# upp_model: IP-XACT component
VLNV IcronTechnologies:IcronTechnologies:upp_model:1.0

## Parameters
addr_width = 10
bus_width = 32

## Bus interfaces (logical=physical port)
default_map: slave AGNISYS:AGNISYS:APB:1.0, memory map uppmap
  pclk=pclk, presetn=presetn, psel=psel, penable=penable, pwrite=pwrite, pprot=pprot, pstrb=pstrb, pwdata=pwdata, paddr=paddr, pready=pready, prdata=prdata, pslverr=pslverr

## Ports
in pclk
in presetn
in psel
in penable
in pwrite
in pprot[2:0]
in pstrb[(bus_width div 8 )-1:0]
in pwdata[bus_width -1:0]
in paddr[addr_width -1:0]
out pready
out prdata[bus_width -1:0]
out pslverr
out upp_regsversion_major_r[7:0]
out upp_regsversion_minor_r[7:0]
out upp_regsversion_patch_r[7:0]
out upp_regsconfig0_enb
out upp_regsconfig0_ping_non_rspns_cnt_r[3:0]
out upp_regsconfig0_dp_max_numb_cnt_r[6:0]
out upp_regsconfig0_dp_max_time_cnt_r[8:0]
out upp_regscontrol_enb
out upp_regscontrol_limit_num_pings_snt_r
out upp_regscontrol_iso_dev_non_rspns_cnt_r[3:0]
out upp_regscontrol_lex_buff_max_cnt_r[5:0]
out upp_regscontrol_disable_itp_delta_r
out upp_regscontrol_max_itp_deviation_2fix_r[9:0]
out upp_regscontrol_limit_max_burst_r
out upp_regscontrol_bulk_term_en_r
out upp_regscontrol_ping_term_en_r
out upp_regscontrol_ctrl_trfr_int_mode_r
out upp_regscontrol_init_ept_r
out upp_regscontrol_itp_gen_r
out upp_regscontrol_itp_manager_en_r
out upp_regscontrol_ctrl_manager_en_r
out upp_regscontrol_clr_ctrl_trfr_mgr_r
out upp_regsid_mgr_fifo_write_engine_config0_clear_enb
out upp_regsid_mgr_fifo_write_engine_config0_clear_wclr_r
out upp_regsid_mgr_fifo_write_engine_config0_mode_enb
out upp_regsid_mgr_fifo_write_engine_config0_mode_drp_on_sop_r
out upp_regsid_mgr_fifo_write_engine_config0_mode_drp_on_pkt_err_r
out upp_regsid_mgr_fifo_write_engine_config0_mode_pkt_strm_r
out upp_regsid_mgr_fifo_write_engine_config0_mode_flw_ctrl_en_r
out upp_regsid_mgr_fifo_write_engine_config0_notify_limit_enb
out upp_regsid_mgr_fifo_write_engine_config0_notify_limit_ntfy_lmt_r[31:0]
out upp_regsid_mgr_fifo_write_engine_stats0_rd2clr_config_rd_valid_out
out upp_regsid_mgr_fifo_write_engine_stats0_rd2clr_config_wr_valid_out
out upp_regsid_mgr_fifo_write_engine_stats0_nfifo_dcount_rd_valid_out
out upp_regsid_mgr_fifo_write_engine_stats0_pfifo_dcount_rd_valid_out
out upp_regsid_mgr_fifo_write_engine_stats0_pkt_max_byte_cnt_err_rd_valid_out
out upp_regsid_mgr_fifo_write_engine_stats0_fifo_full_err_rd_valid_out
out upp_regsid_mgr_fifo_write_engine_stats0_pkt_err_rd_valid_out
out upp_regsid_mgr_fifo_write_engine_stats0_pkt_sop_err_rd_valid_out
out upp_regsid_mgr_fifo_write_engine_stats0_wflush_act_rd_valid_out
out upp_regsid_mgr_fifo_write_engine_stats0_drp_pkt_rd_rd_valid_out
out upp_regsid_mgr_fifo_write_engine_stats0_drp_pkt_wr_rd_valid_out
out upp_regsid_mgr_fifo_write_engine_stats0_flow_ctrl_rd_valid_out
out upp_regsid_mgr_fifo_read_engine_config0_clear_enb
out upp_regsid_mgr_fifo_read_engine_config0_clear_rclr_r
out upp_regsid_mgr_fifo_read_engine_stats0_rd2clr_config_rd_valid_out
out upp_regsid_mgr_fifo_read_engine_stats0_rd2clr_config_wr_valid_out
out upp_regsid_mgr_fifo_read_engine_stats0_rflush_act_rd_valid_out
out upp_regsid_mgr_fifo_read_engine_stats0_drp_pkt_rd_valid_out
out upp_regsid_mgr_fifo_read_engine_stats0_flow_ctrl_rd_valid_out
out upp_regsiso_lex_fifo_{n}_write_engine_config0_clear_enb (n=0..3)
out upp_regsiso_lex_fifo_{n}_write_engine_config0_clear_wclr_r (n=0..3)
out upp_regsiso_lex_fifo_{n}_write_engine_config0_mode_enb (n=0..3)
out upp_regsiso_lex_fifo_{n}_write_engine_config0_mode_drp_on_sop_r (n=0..3)
out upp_regsiso_lex_fifo_{n}_write_engine_config0_mode_drp_on_pkt_err_r (n=0..3)
out upp_regsiso_lex_fifo_{n}_write_engine_config0_mode_pkt_strm_r (n=0..3)
out upp_regsiso_lex_fifo_{n}_write_engine_config0_mode_flw_ctrl_en_r (n=0..3)
out upp_regsiso_lex_fifo_{n}_write_engine_config0_notify_limit_enb (n=0..3)
out upp_regsiso_lex_fifo_{n}_write_engine_config0_notify_limit_ntfy_lmt_r[31:0] (n=0..3)
out upp_regsiso_lex_fifo_{n}_write_engine_stats0_rd2clr_config_rd_valid_out (n=0..3)
out upp_regsiso_lex_fifo_{n}_write_engine_stats0_rd2clr_config_wr_valid_out (n=0..3)
out upp_regsiso_lex_fifo_{n}_write_engine_stats0_nfifo_dcount_rd_valid_out (n=0..3)
out upp_regsiso_lex_fifo_{n}_write_engine_stats0_pfifo_dcount_rd_valid_out (n=0..3)
out upp_regsiso_lex_fifo_{n}_write_engine_stats0_pkt_max_byte_cnt_err_rd_valid_out (n=0..3)
out upp_regsiso_lex_fifo_{n}_write_engine_stats0_fifo_full_err_rd_valid_out (n=0..3)
out upp_regsiso_lex_fifo_{n}_write_engine_stats0_pkt_err_rd_valid_out (n=0..3)
out upp_regsiso_lex_fifo_{n}_write_engine_stats0_pkt_sop_err_rd_valid_out (n=0..3)
out upp_regsiso_lex_fifo_{n}_write_engine_stats0_wflush_act_rd_valid_out (n=0..3)
out upp_regsiso_lex_fifo_{n}_write_engine_stats0_drp_pkt_rd_rd_valid_out (n=0..3)
out upp_regsiso_lex_fifo_{n}_write_engine_stats0_drp_pkt_wr_rd_valid_out (n=0..3)
out upp_regsiso_lex_fifo_{n}_write_engine_stats0_flow_ctrl_rd_valid_out (n=0..3)
out upp_regsiso_lex_fifo_{n}_read_engine_config0_clear_enb (n=0..3)
out upp_regsiso_lex_fifo_{n}_read_engine_config0_clear_rclr_r (n=0..3)
out upp_regsiso_lex_fifo_{n}_read_engine_stats0_rd2clr_config_rd_valid_out (n=0..3)
out upp_regsiso_lex_fifo_{n}_read_engine_stats0_rd2clr_config_wr_valid_out (n=0..3)
out upp_regsiso_lex_fifo_{n}_read_engine_stats0_rflush_act_rd_valid_out (n=0..3)
out upp_regsiso_lex_fifo_{n}_read_engine_stats0_drp_pkt_rd_valid_out (n=0..3)
out upp_regsiso_lex_fifo_{n}_read_engine_stats0_flow_ctrl_rd_valid_out (n=0..3)
out upp_regsiso_rex_fifo_write_engine_config0_clear_enb
out upp_regsiso_rex_fifo_write_engine_config0_clear_wclr_r
out upp_regsiso_rex_fifo_write_engine_config0_mode_enb
out upp_regsiso_rex_fifo_write_engine_config0_mode_drp_on_sop_r
out upp_regsiso_rex_fifo_write_engine_config0_mode_drp_on_pkt_err_r
out upp_regsiso_rex_fifo_write_engine_config0_mode_pkt_strm_r
out upp_regsiso_rex_fifo_write_engine_config0_mode_flw_ctrl_en_r
out upp_regsiso_rex_fifo_write_engine_config0_notify_limit_enb
out upp_regsiso_rex_fifo_write_engine_config0_notify_limit_ntfy_lmt_r[31:0]
out upp_regsiso_rex_fifo_write_engine_stats0_rd2clr_config_rd_valid_out
out upp_regsiso_rex_fifo_write_engine_stats0_rd2clr_config_wr_valid_out
out upp_regsiso_rex_fifo_write_engine_stats0_nfifo_dcount_rd_valid_out
out upp_regsiso_rex_fifo_write_engine_stats0_pfifo_dcount_rd_valid_out
out upp_regsiso_rex_fifo_write_engine_stats0_pkt_max_byte_cnt_err_rd_valid_out
out upp_regsiso_rex_fifo_write_engine_stats0_fifo_full_err_rd_valid_out
out upp_regsiso_rex_fifo_write_engine_stats0_pkt_err_rd_valid_out
out upp_regsiso_rex_fifo_write_engine_stats0_pkt_sop_err_rd_valid_out
out upp_regsiso_rex_fifo_write_engine_stats0_wflush_act_rd_valid_out
out upp_regsiso_rex_fifo_write_engine_stats0_drp_pkt_rd_rd_valid_out
out upp_regsiso_rex_fifo_write_engine_stats0_drp_pkt_wr_rd_valid_out
out upp_regsiso_rex_fifo_write_engine_stats0_flow_ctrl_rd_valid_out
out upp_regsiso_rex_fifo_read_engine_config0_clear_enb
out upp_regsiso_rex_fifo_read_engine_config0_clear_rclr_r
out upp_regsiso_rex_fifo_read_engine_stats0_rd2clr_config_rd_valid_out
out upp_regsiso_rex_fifo_read_engine_stats0_rd2clr_config_wr_valid_out
out upp_regsiso_rex_fifo_read_engine_stats0_rflush_act_rd_valid_out
out upp_regsiso_rex_fifo_read_engine_stats0_drp_pkt_rd_valid_out
out upp_regsiso_rex_fifo_read_engine_stats0_flow_ctrl_rd_valid_out
out upp_regsctrl_trfr_h2d_fifo_write_engine_config0_clear_enb
out upp_regsctrl_trfr_h2d_fifo_write_engine_config0_clear_wclr_r
out upp_regsctrl_trfr_h2d_fifo_write_engine_config0_mode_enb
out upp_regsctrl_trfr_h2d_fifo_write_engine_config0_mode_drp_on_sop_r
out upp_regsctrl_trfr_h2d_fifo_write_engine_config0_mode_drp_on_pkt_err_r
out upp_regsctrl_trfr_h2d_fifo_write_engine_config0_mode_pkt_strm_r
out upp_regsctrl_trfr_h2d_fifo_write_engine_config0_mode_flw_ctrl_en_r
out upp_regsctrl_trfr_h2d_fifo_write_engine_config0_notify_limit_enb
out upp_regsctrl_trfr_h2d_fifo_write_engine_config0_notify_limit_ntfy_lmt_r[31:0]
out upp_regsctrl_trfr_h2d_fifo_write_engine_stats0_rd2clr_config_rd_valid_out
out upp_regsctrl_trfr_h2d_fifo_write_engine_stats0_rd2clr_config_wr_valid_out
out upp_regsctrl_trfr_h2d_fifo_write_engine_stats0_nfifo_dcount_rd_valid_out
out upp_regsctrl_trfr_h2d_fifo_write_engine_stats0_pfifo_dcount_rd_valid_out
out upp_regsctrl_trfr_h2d_fifo_write_engine_stats0_pkt_max_byte_cnt_err_rd_valid_out
out upp_regsctrl_trfr_h2d_fifo_write_engine_stats0_fifo_full_err_rd_valid_out
out upp_regsctrl_trfr_h2d_fifo_write_engine_stats0_pkt_err_rd_valid_out
out upp_regsctrl_trfr_h2d_fifo_write_engine_stats0_pkt_sop_err_rd_valid_out
out upp_regsctrl_trfr_h2d_fifo_write_engine_stats0_wflush_act_rd_valid_out
out upp_regsctrl_trfr_h2d_fifo_write_engine_stats0_drp_pkt_rd_rd_valid_out
out upp_regsctrl_trfr_h2d_fifo_write_engine_stats0_drp_pkt_wr_rd_valid_out
out upp_regsctrl_trfr_h2d_fifo_write_engine_stats0_flow_ctrl_rd_valid_out
out upp_regsctrl_trfr_h2d_fifo_read_engine_config0_clear_enb
out upp_regsctrl_trfr_h2d_fifo_read_engine_config0_clear_rclr_r
out upp_regsctrl_trfr_h2d_fifo_read_engine_stats0_rd2clr_config_rd_valid_out
out upp_regsctrl_trfr_h2d_fifo_read_engine_stats0_rd2clr_config_wr_valid_out
out upp_regsctrl_trfr_h2d_fifo_read_engine_stats0_rflush_act_rd_valid_out
out upp_regsctrl_trfr_h2d_fifo_read_engine_stats0_drp_pkt_rd_valid_out
out upp_regsctrl_trfr_h2d_fifo_read_engine_stats0_flow_ctrl_rd_valid_out
out upp_regsctrl_trfr_d2h_fifo_write_engine_config0_clear_enb
out upp_regsctrl_trfr_d2h_fifo_write_engine_config0_clear_wclr_r
out upp_regsctrl_trfr_d2h_fifo_write_engine_config0_mode_enb
out upp_regsctrl_trfr_d2h_fifo_write_engine_config0_mode_drp_on_sop_r
out upp_regsctrl_trfr_d2h_fifo_write_engine_config0_mode_drp_on_pkt_err_r
out upp_regsctrl_trfr_d2h_fifo_write_engine_config0_mode_pkt_strm_r
out upp_regsctrl_trfr_d2h_fifo_write_engine_config0_mode_flw_ctrl_en_r
out upp_regsctrl_trfr_d2h_fifo_write_engine_config0_notify_limit_enb
out upp_regsctrl_trfr_d2h_fifo_write_engine_config0_notify_limit_ntfy_lmt_r[31:0]
out upp_regsctrl_trfr_d2h_fifo_write_engine_stats0_rd2clr_config_rd_valid_out
out upp_regsctrl_trfr_d2h_fifo_write_engine_stats0_rd2clr_config_wr_valid_out
out upp_regsctrl_trfr_d2h_fifo_write_engine_stats0_nfifo_dcount_rd_valid_out
out upp_regsctrl_trfr_d2h_fifo_write_engine_stats0_pfifo_dcount_rd_valid_out
out upp_regsctrl_trfr_d2h_fifo_write_engine_stats0_pkt_max_byte_cnt_err_rd_valid_out
out upp_regsctrl_trfr_d2h_fifo_write_engine_stats0_fifo_full_err_rd_valid_out
out upp_regsctrl_trfr_d2h_fifo_write_engine_stats0_pkt_err_rd_valid_out
out upp_regsctrl_trfr_d2h_fifo_write_engine_stats0_pkt_sop_err_rd_valid_out
out upp_regsctrl_trfr_d2h_fifo_write_engine_stats0_wflush_act_rd_valid_out
out upp_regsctrl_trfr_d2h_fifo_write_engine_stats0_drp_pkt_rd_rd_valid_out
out upp_regsctrl_trfr_d2h_fifo_write_engine_stats0_drp_pkt_wr_rd_valid_out
out upp_regsctrl_trfr_d2h_fifo_write_engine_stats0_flow_ctrl_rd_valid_out
out upp_regsctrl_trfr_d2h_fifo_read_engine_config0_clear_enb
out upp_regsctrl_trfr_d2h_fifo_read_engine_config0_clear_rclr_r
out upp_regsctrl_trfr_d2h_fifo_read_engine_stats0_rd2clr_config_rd_valid_out
out upp_regsctrl_trfr_d2h_fifo_read_engine_stats0_rd2clr_config_wr_valid_out
out upp_regsctrl_trfr_d2h_fifo_read_engine_stats0_rflush_act_rd_valid_out
out upp_regsctrl_trfr_d2h_fifo_read_engine_stats0_drp_pkt_rd_valid_out
out upp_regsctrl_trfr_d2h_fifo_read_engine_stats0_flow_ctrl_rd_valid_out
out upp_regsctrl_trfr_h2d_data_rd_valid_out
out upp_regsctrl_trfr_h2d_ctrl_rd_valid_out
out upp_regsctrl_trfr_h2d_skip_enb
out upp_regsctrl_trfr_h2d_skip_cycles_r[7:0]
out upp_regsregctrl_trfr_h2d_skip_cycles_wr_pulse
out upp_regsctrl_trfr_h2d_dbg_enb
out upp_regsctrl_trfr_h2d_dbg_squelch_en_r
out upp_regsctrl_trfr_h2d_dbg_crc32_term_value_r[9:0]
out upp_regsctrl_trfr_h2d_dbg_crc32_err_inj_en_r
out upp_regsctrl_trfr_d2h_data_rd_valid_out
out upp_regsctrl_trfr_d2h_ctrl_rd_valid_out
out upp_regsctrl_trfr_d2h_skip_enb
out upp_regsctrl_trfr_d2h_skip_cycles_r[7:0]
out upp_regsregctrl_trfr_d2h_skip_cycles_wr_pulse
out upp_regsctrl_trfr_d2h_dbg_enb
out upp_regsctrl_trfr_d2h_dbg_squelch_en_r
out upp_regsctrl_trfr_d2h_dbg_crc32_term_value_r[9:0]
out upp_regsctrl_trfr_d2h_dbg_crc32_err_inj_en_r
out upp_regsctrl_trfr_cmpltd_enb
out upp_regsctrl_trfr_cmpltd_device_addr_r[6:0]
out upp_regsregctrl_trfr_cmpltd_device_addr_wr_pulse
out upp_regsendpoint_tbl_config0_enb
out upp_regsendpoint_tbl_config0_null_en_r
out upp_regsendpoint_tbl_config0_bm_attributes_tt_r[1:0]
out upp_regsendpoint_tbl_config0_qid_r[7:0]
out upp_regsendpoint_tbl_config0_device_addr_r[6:0]
out upp_regsendpoint_tbl_config0_ept_num_r[3:0]
out upp_regsregendpoint_tbl_config0_ept_num_wr_pulse
out upp_regsendpoint_tbl_config1_enb
out upp_regsendpoint_tbl_config1_crdt_chk_value_r[1:0]
out upp_regsendpoint_tbl_config1_max_burst_r[3:0]
out upp_regsendpoint_tbl_config1_coded_binterval_r[15:0]
out upp_regsstats0_rd2clr_config_rd_valid_out
out upp_regsstats0_rd2clr_config_wr_valid_out
out upp_regsstats0_missing_itp_rd_valid_out

## Address spaces and blocks
uppmap.upp: base 0x000, range 0x300, width 32

## Registers
Registers are 32-bit, read-only, reset 0x0 unless marked. A register's access mark holds for its fields unless they carry their own. Offsets are from the block's base; lines under a group give offsets from that group; [hi:lo] are bit positions; {n}, {i} and the like mark numbered series; 'fields as' and 'values as' point back to an identical list; <NAME> marks a mode.

## uppmap.upp — UPP Registers
Base 0x00000000
0x00 version reset 0x40400 — Version: 2.0.0: Adding the Control Transfer Manager and CT-Processor to the Design 3.0.0: Adding the ITP Manager, Endpoint Table, CTIM Time Tag and Skip Function, etc 3.1.0: Adding Max Burst to the Endpoint Table 3.2.0: Changed the Interrupt Pending to avoid blocking the register update when enable is 0 3.3.0: Added pending_irq register and Add Ping and Bulk IN Termination 4.0.0: Adding BInterval and Independent ISO REX Scheduling for Service Interval Binning. Also, add LEX PFIFOs and ITP Registers 4.1.0: Cleanup register map and added ISO Null Queue 4.1.1: Removed mark_debug and also added read pipline for the PFIFO to improve timing 4.2.0: Add interrupts for ISO Device Non-Response. 4.3.0: Add interrupts for PING not responding 4.3.1: Remove Latches 4.4.0: Use CPU Plug IPs rather than stand alone logic for h2d and d2h
  [23:16] major — Major version
  [15:8] minor — Minor version
  [7:0] patch — Patch version
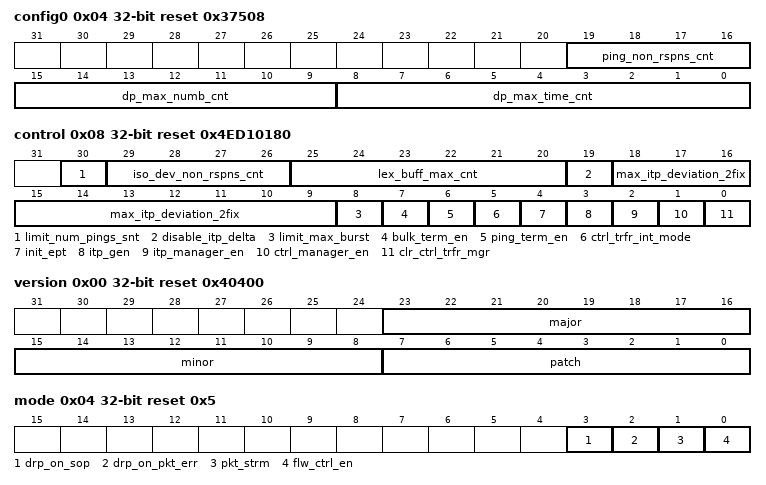
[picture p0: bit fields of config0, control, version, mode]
0x04 config0 rw reset 0x37508
  [19:16] ping_non_rspns_cnt — Every Service Interval when a PING is sent to the device and a PING RESPONSE is not received, a count is incremented. When the counter reaches this value, it will issue an interrupt to software
  [15:9] dp_max_numb_cnt — This is the total number of full-size DP packets that needs to be allocated in one ITP. This value together with dp_max_time_cnt divide an ITP period into multiple section of available "credits". The "credits" are used to schedule ISO packets such that they don't fall on ITP boundary.
  [8:0] dp_max_time_cnt — Maximum "cycle" time for one DP packet. This is typically 2.117 us and for our 4-byte implementation and clock period of 8 ns (125MHz frequency) it is about 264. This counter value with the help of dp_max_numb_cnt divide an ITP period into multiple sections of available "credits". The "credits" are used to schedule ISO packets such that they don't fall on ITP boundary.
0x08 control rw reset 0x4ED10180
  [30] limit_num_pings_snt — Set to 1 to limit the number of PING Request sent to one PING in every 2ms (when device is not responding to PING). To avoid flooding the REX Hub that can cause credit_hp_timer firing, the default is enabled such that it only sends a PING requests every ~2ms when device is not responding (when device is disconnected).
  [29:26] iso_dev_non_rspns_cnt — Every Service Interval when the device is asked for data and it does not respond at least with one DP, a count is incremented. When the counter reaches this value, it will issue an interrupt to software.
  [25:20] lex_buff_max_cnt — This is maximum full DP size of the LEX buffers in each ISO (accelerated) queue. This is used on the REX to follow the buffer occupancy on the LEX. Typical value should be less than 45
  [19] disable_itp_delta — Set to 1 to disable modifying the ITP Delta field in the Isochronous Timestamp (ITS) of Table 8-26 Section 8.7.
  [18:9] max_itp_deviation_2fix — Maximum deviation of incoming ITP from Bus Boundary for the ITP Manager to fix immediately. This number should be (deviation us/8 ns). Default value of 128 represents about 1us deviation
  [8] limit_max_burst — Set to 0 to let the REX ISO Scheduler to base its burst size on the device Max Burst. By default, the burst size follows the host value.
  [7] bulk_term_en — Set to 0 to disable BULK IN Termination Method (BITM)
  [6] ping_term_en — Set to 1 to enable the Ping Termination Method (PTM) that terminates the PING protocol in UPP
  [5] ctrl_trfr_int_mode — When 0, the ctrl_trfr (h2d and d2h) interrupts are packet based (rising sop). When 1, the interrupt is cycle based (each srdy causes interrupt)
  [4] init_ept — Assert high to clear and initialize the EndPoint Table (EPT).
  [3] itp_gen — Assert high to instruct the ITP Manager on the REX, when it is enabled, to independently start sending ITP packets to the device as soon as its Link Layer is in U0.
  [2] itp_manager_en — Assert high to have the ITP Manager on the REX enabled such that it can track the ITPs from the Host and independently issue an ITP when the 125us timer elapses and no ITP is received.
  [1] ctrl_manager_en — Assert high to enable the Control Transfer Manager. When not enabled, the UPP does not interfere with or terminate Control Transfers. As the result, Host and Device will interact directly.
  [0] clr_ctrl_trfr_mgr — Assert high to clear all the state tables in the Control Transfer Manager
0x0C id_mgr_fifo group
  0x00 version reset 0x10100 — Version 1.1.0: Added Icron Attributes for stats script generation
    fields as version
  0x04 write_engine group
    0x00 config0 group
      0x00 clear rw — Synchronous clear for the write clock domain
        [0] wclr
      0x04 mode rw reset 0x5
        [3] drp_on_sop — When set, drops the current packet without writing it to the buffer. See Wiki
        [2] drp_on_pkt_err — When set, removes the packet from the buffer without presenting it to the output interface upon the ERR bit being set before the notification point. See Wiki
        [1] pkt_strm — Selects packet based or streaming based behavior. See Wiki
        [0] flw_ctrl_en — Enables the flow control. See Wiki
      0x08 notify_limit rw
        [31:0] ntfy_lmt — Sets the number of words required to be written into the packet FIFO before a notification will be generated. See wiki
    0x0C stats0 group — All the Statistic Registers and their configuration for the Write Engine
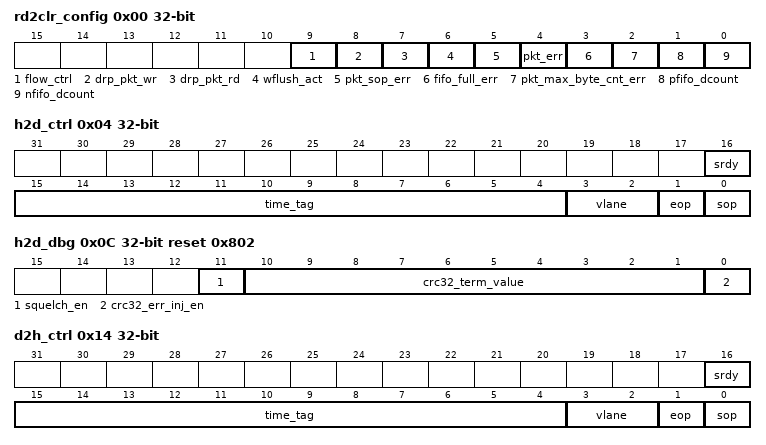
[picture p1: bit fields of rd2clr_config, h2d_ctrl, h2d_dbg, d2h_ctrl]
      0x00 rd2clr_config rw — Configures if the stats register read by s/w clears the read register. A 1 in any bit configures the h/w to clear the corresponding stats register after a s/w read of that stats register.
        [9] flow_ctrl, [8] drp_pkt_wr, [7] drp_pkt_rd, [6] wflush_act, [5] pkt_sop_err, [4] pkt_err, [3] fifo_full_err, [2] pkt_max_byte_cnt_err, [1] pfifo_dcount, [0] nfifo_dcount
      0x04 nfifo_dcount — Current level for the notification FIFO in the PFIFO
        [15:0] nfifo_dcount — _icron_water_marker_ _icron_no_counter_
      0x08 pfifo_dcount — Current level for the packet FIFO in the PFIFO
        [15:0] pfifo_dcount — _icron_water_marker_ _icron_no_counter_
      0x0C pkt_max_byte_cnt_err — The count for capped packets in PFIFO write engine, as the result of reaching maximum size in the PFIFO
        [7:0] pkt_max_byte_cnt_err
      0x10 fifo_full_err — The count for either of PFIFO or NFIFO being full
        [7:0] fifo_full_err
      0x14 pkt_err — The count of packets tagged to be dropped later in the PFIFO read engine
        [7:0] pkt_err
      0x18 pkt_sop_err — The count of packets flushed in the PFIFO during the SOP phase
        [7:0] pkt_sop_err
      0x1C wflush_act — The count of capped packets in the PFIFO. Note that back-to-back packets are counted as one if they are both capped.
        [7:0] wflush_act — _icron_event_detect_rising_edge_
      0x20 drp_pkt_rd — The count of drop packets flagged to be dropped by the read engine
        [7:0] drp_pkt_rd
      0x24 drp_pkt_wr — The count of drop packets by the write engine
        [7:0] drp_pkt_wr
      0x28 flow_ctrl — The count of the clock cycles the DRDY is asserted low resulting in flow control
        [15:0] flow_ctrl
  0x3C read_engine group
    0x00 config0 group
      0x00 clear rw — Synchronous clear for the read clock domain
        [0] rclr
    0x04 stats0 group — All the Statistic Registers and their configuration for the Read Engine
      0x00 rd2clr_config rw — Configures if the stats register read by s/w clears the read register. A 1 in any bit configures the h/w to clear the corresponding stats register after a s/w read of that stats register.
        [2] flow_ctrl, [1] drp_pkt, [0] rflush_act
      0x04 rflush_act — The counts of number of packets flushed from the PFIFO.
        [7:0] rflush_act — _icron_event_detect_rising_edge_
      0x08 drp_pkt — The counts of drop packet in the PFIFO read engine
        [7:0] drp_pkt
      0x0C flow_ctrl — The count of the clock cycles the DRDY is asserted low resulting in flow control
        [15:0] flow_ctrl
{0x5C+0x50*i} iso_lex_fifo_{i} group (i=0..3)
  0x00 version reset 0x10100 — Version 1.1.0: Added Icron Attributes for stats script generation
    fields as version
  0x04 write_engine group
    0x00 config0 group
      0x00 clear rw — Synchronous clear for the write clock domain
        [0] wclr
      0x04 mode rw reset 0x5
        fields as id_mgr_fifo.write_engine.config0.mode
      0x08 notify_limit rw
        fields as id_mgr_fifo.write_engine.config0.notify_limit
    0x0C stats0 group — All the Statistic Registers and their configuration for the Write Engine
      0x00 rd2clr_config rw — Configures if the stats register read by s/w clears the read register. A 1 in any bit configures the h/w to clear the corresponding stats register after a s/w read of that stats register.
        fields as id_mgr_fifo.write_engine.stats0.rd2clr_config
      0x04 nfifo_dcount — Current level for the notification FIFO in the PFIFO
        [15:0] nfifo_dcount — _icron_water_marker_ _icron_no_counter_
      0x08 pfifo_dcount — Current level for the packet FIFO in the PFIFO
        [15:0] pfifo_dcount — _icron_water_marker_ _icron_no_counter_
      0x0C pkt_max_byte_cnt_err — The count for capped packets in PFIFO write engine, as the result of reaching maximum size in the PFIFO
        [7:0] pkt_max_byte_cnt_err
      0x10 fifo_full_err — The count for either of PFIFO or NFIFO being full
        [7:0] fifo_full_err
      0x14 pkt_err — The count of packets tagged to be dropped later in the PFIFO read engine
        [7:0] pkt_err
      0x18 pkt_sop_err — The count of packets flushed in the PFIFO during the SOP phase
        [7:0] pkt_sop_err
      0x1C wflush_act — The count of capped packets in the PFIFO. Note that back-to-back packets are counted as one if they are both capped.
        [7:0] wflush_act — _icron_event_detect_rising_edge_
      0x20 drp_pkt_rd — The count of drop packets flagged to be dropped by the read engine
        [7:0] drp_pkt_rd
      0x24 drp_pkt_wr — The count of drop packets by the write engine
        [7:0] drp_pkt_wr
      0x28 flow_ctrl — The count of the clock cycles the DRDY is asserted low resulting in flow control
        [15:0] flow_ctrl
  0x3C read_engine group
    0x00 config0 group
      0x00 clear rw — Synchronous clear for the read clock domain
        [0] rclr
    0x04 stats0 group — All the Statistic Registers and their configuration for the Read Engine
      0x00 rd2clr_config rw — Configures if the stats register read by s/w clears the read register. A 1 in any bit configures the h/w to clear the corresponding stats register after a s/w read of that stats register.
        [2] flow_ctrl, [1] drp_pkt, [0] rflush_act
      0x04 rflush_act — The counts of number of packets flushed from the PFIFO.
        [7:0] rflush_act — _icron_event_detect_rising_edge_
      0x08 drp_pkt — The counts of drop packet in the PFIFO read engine
        [7:0] drp_pkt
      0x0C flow_ctrl — The count of the clock cycles the DRDY is asserted low resulting in flow control
        [15:0] flow_ctrl
0x19C iso_rex_fifo group
  0x00 version reset 0x10100 — Version 1.1.0: Added Icron Attributes for stats script generation
    fields as version
  0x04 write_engine group
    0x00 config0 group
      0x00 clear rw — Synchronous clear for the write clock domain
        [0] wclr
      0x04 mode rw reset 0x5
        fields as id_mgr_fifo.write_engine.config0.mode
      0x08 notify_limit rw
        fields as id_mgr_fifo.write_engine.config0.notify_limit
    0x0C stats0 group — All the Statistic Registers and their configuration for the Write Engine
      0x00 rd2clr_config rw — Configures if the stats register read by s/w clears the read register. A 1 in any bit configures the h/w to clear the corresponding stats register after a s/w read of that stats register.
        fields as id_mgr_fifo.write_engine.stats0.rd2clr_config
      0x04 nfifo_dcount — Current level for the notification FIFO in the PFIFO
        [15:0] nfifo_dcount — _icron_water_marker_ _icron_no_counter_
      0x08 pfifo_dcount — Current level for the packet FIFO in the PFIFO
        [15:0] pfifo_dcount — _icron_water_marker_ _icron_no_counter_
      0x0C pkt_max_byte_cnt_err — The count for capped packets in PFIFO write engine, as the result of reaching maximum size in the PFIFO
        [7:0] pkt_max_byte_cnt_err
      0x10 fifo_full_err — The count for either of PFIFO or NFIFO being full
        [7:0] fifo_full_err
      0x14 pkt_err — The count of packets tagged to be dropped later in the PFIFO read engine
        [7:0] pkt_err
      0x18 pkt_sop_err — The count of packets flushed in the PFIFO during the SOP phase
        [7:0] pkt_sop_err
      0x1C wflush_act — The count of capped packets in the PFIFO. Note that back-to-back packets are counted as one if they are both capped.
        [7:0] wflush_act — _icron_event_detect_rising_edge_
      0x20 drp_pkt_rd — The count of drop packets flagged to be dropped by the read engine
        [7:0] drp_pkt_rd
      0x24 drp_pkt_wr — The count of drop packets by the write engine
        [7:0] drp_pkt_wr
      0x28 flow_ctrl — The count of the clock cycles the DRDY is asserted low resulting in flow control
        [15:0] flow_ctrl
  0x3C read_engine group
    0x00 config0 group
      0x00 clear rw — Synchronous clear for the read clock domain
        [0] rclr
    0x04 stats0 group — All the Statistic Registers and their configuration for the Read Engine
      0x00 rd2clr_config rw — Configures if the stats register read by s/w clears the read register. A 1 in any bit configures the h/w to clear the corresponding stats register after a s/w read of that stats register.
        [2] flow_ctrl, [1] drp_pkt, [0] rflush_act
      0x04 rflush_act — The counts of number of packets flushed from the PFIFO.
        [7:0] rflush_act — _icron_event_detect_rising_edge_
      0x08 drp_pkt — The counts of drop packet in the PFIFO read engine
        [7:0] drp_pkt
      0x0C flow_ctrl — The count of the clock cycles the DRDY is asserted low resulting in flow control
        [15:0] flow_ctrl
0x1EC ctrl_trfr_h2d_fifo group
  0x00 version reset 0x10100 — Version 1.1.0: Added Icron Attributes for stats script generation
    fields as version
  0x04 write_engine group
    0x00 config0 group
      0x00 clear rw — Synchronous clear for the write clock domain
        [0] wclr
      0x04 mode rw reset 0x5
        fields as id_mgr_fifo.write_engine.config0.mode
      0x08 notify_limit rw
        fields as id_mgr_fifo.write_engine.config0.notify_limit
    0x0C stats0 group — All the Statistic Registers and their configuration for the Write Engine
      0x00 rd2clr_config rw — Configures if the stats register read by s/w clears the read register. A 1 in any bit configures the h/w to clear the corresponding stats register after a s/w read of that stats register.
        fields as id_mgr_fifo.write_engine.stats0.rd2clr_config
      0x04 nfifo_dcount — Current level for the notification FIFO in the PFIFO
        [15:0] nfifo_dcount — _icron_water_marker_ _icron_no_counter_
      0x08 pfifo_dcount — Current level for the packet FIFO in the PFIFO
        [15:0] pfifo_dcount — _icron_water_marker_ _icron_no_counter_
      0x0C pkt_max_byte_cnt_err — The count for capped packets in PFIFO write engine, as the result of reaching maximum size in the PFIFO
        [7:0] pkt_max_byte_cnt_err
      0x10 fifo_full_err — The count for either of PFIFO or NFIFO being full
        [7:0] fifo_full_err
      0x14 pkt_err — The count of packets tagged to be dropped later in the PFIFO read engine
        [7:0] pkt_err
      0x18 pkt_sop_err — The count of packets flushed in the PFIFO during the SOP phase
        [7:0] pkt_sop_err
      0x1C wflush_act — The count of capped packets in the PFIFO. Note that back-to-back packets are counted as one if they are both capped.
        [7:0] wflush_act — _icron_event_detect_rising_edge_
      0x20 drp_pkt_rd — The count of drop packets flagged to be dropped by the read engine
        [7:0] drp_pkt_rd
      0x24 drp_pkt_wr — The count of drop packets by the write engine
        [7:0] drp_pkt_wr
      0x28 flow_ctrl — The count of the clock cycles the DRDY is asserted low resulting in flow control
        [15:0] flow_ctrl
  0x3C read_engine group
    0x00 config0 group
      0x00 clear rw — Synchronous clear for the read clock domain
        [0] rclr
    0x04 stats0 group — All the Statistic Registers and their configuration for the Read Engine
      0x00 rd2clr_config rw — Configures if the stats register read by s/w clears the read register. A 1 in any bit configures the h/w to clear the corresponding stats register after a s/w read of that stats register.
        [2] flow_ctrl, [1] drp_pkt, [0] rflush_act
      0x04 rflush_act — The counts of number of packets flushed from the PFIFO.
        [7:0] rflush_act — _icron_event_detect_rising_edge_
      0x08 drp_pkt — The counts of drop packet in the PFIFO read engine
        [7:0] drp_pkt
      0x0C flow_ctrl — The count of the clock cycles the DRDY is asserted low resulting in flow control
        [15:0] flow_ctrl
0x23C ctrl_trfr_d2h_fifo group
  0x00 version reset 0x10100 — Version 1.1.0: Added Icron Attributes for stats script generation
    fields as version
  0x04 write_engine group
    0x00 config0 group
      0x00 clear rw — Synchronous clear for the write clock domain
        [0] wclr
      0x04 mode rw reset 0x5
        fields as id_mgr_fifo.write_engine.config0.mode
      0x08 notify_limit rw
        fields as id_mgr_fifo.write_engine.config0.notify_limit
    0x0C stats0 group — All the Statistic Registers and their configuration for the Write Engine
      0x00 rd2clr_config rw — Configures if the stats register read by s/w clears the read register. A 1 in any bit configures the h/w to clear the corresponding stats register after a s/w read of that stats register.
        fields as id_mgr_fifo.write_engine.stats0.rd2clr_config
      0x04 nfifo_dcount — Current level for the notification FIFO in the PFIFO
        [15:0] nfifo_dcount — _icron_water_marker_ _icron_no_counter_
      0x08 pfifo_dcount — Current level for the packet FIFO in the PFIFO
        [15:0] pfifo_dcount — _icron_water_marker_ _icron_no_counter_
      0x0C pkt_max_byte_cnt_err — The count for capped packets in PFIFO write engine, as the result of reaching maximum size in the PFIFO
        [7:0] pkt_max_byte_cnt_err
      0x10 fifo_full_err — The count for either of PFIFO or NFIFO being full
        [7:0] fifo_full_err
      0x14 pkt_err — The count of packets tagged to be dropped later in the PFIFO read engine
        [7:0] pkt_err
      0x18 pkt_sop_err — The count of packets flushed in the PFIFO during the SOP phase
        [7:0] pkt_sop_err
      0x1C wflush_act — The count of capped packets in the PFIFO. Note that back-to-back packets are counted as one if they are both capped.
        [7:0] wflush_act — _icron_event_detect_rising_edge_
      0x20 drp_pkt_rd — The count of drop packets flagged to be dropped by the read engine
        [7:0] drp_pkt_rd
      0x24 drp_pkt_wr — The count of drop packets by the write engine
        [7:0] drp_pkt_wr
      0x28 flow_ctrl — The count of the clock cycles the DRDY is asserted low resulting in flow control
        [15:0] flow_ctrl
  0x3C read_engine group
    0x00 config0 group
      0x00 clear rw — Synchronous clear for the read clock domain
        [0] rclr
    0x04 stats0 group — All the Statistic Registers and their configuration for the Read Engine
      0x00 rd2clr_config rw — Configures if the stats register read by s/w clears the read register. A 1 in any bit configures the h/w to clear the corresponding stats register after a s/w read of that stats register.
        [2] flow_ctrl, [1] drp_pkt, [0] rflush_act
      0x04 rflush_act — The counts of number of packets flushed from the PFIFO.
        [7:0] rflush_act — _icron_event_detect_rising_edge_
      0x08 drp_pkt — The counts of drop packet in the PFIFO read engine
        [7:0] drp_pkt
      0x0C flow_ctrl — The count of the clock cycles the DRDY is asserted low resulting in flow control
        [15:0] flow_ctrl
0x28C ctrl_trfr group — All the Statistic Registers and their configuration
  0x00 h2d_data — Control Transfer packet Data portion for the Host to Device
    [31:0] h2d_data — Data of the packet for Host to Device. Data is filled from the most significant (31:24) byte
  0x04 h2d_ctrl — Control Transfer packet sideband signals for Host to Device
    [16] srdy — Validity of h2d
    [15:4] time_tag — Event time tag recorded in each cycle.
    [3:2] vlane — Valid number of "lanes" where each lane is one bye
    [1] eop — End of Packet
    [0] sop — Start of Packet
  0x08 h2d_skip rw — This register allows the software to skip certain number of cycles in the h2d data and control registers.
    [7:0] cycles — Write once into this register with the number of cycles that the h2d_data and h2d_ctrl need to be skipped. A zero value will skip to the eop of the packet.
  0x0C h2d_dbg rw reset 0x802
    [11] squelch_en — Set to 1 to zero out the data sent to the SW when injecting CRC32 error in the Control Transfer. Note that the data is squelched from the third cycle (from bytes 9) onwards, including the CRC32. Also note that the data is NOT squelched to the Device and only CRC32 is errored.
    [10:1] crc32_term_value — Every time a Control data packet is seen, a counter is incremented. When this terminus value is reached, the counter resets back to 0. Note value of 0 is NOT valid.
    [0] crc32_err_inj_en — Set to 1 to enable the CRC32 error injection logic and counter in the Control Transfers. When enabled, the counter is enabled and the logic will inject CRC32 errors when the crc32_term_value is reached in the counter.
  0x10 d2h_data — Control Transfer packet Data portion for the Device to Host
    [31:0] d2h_data — Data of the packet for Device to Host. Data is filled from the most significant (31:24) byte
  0x14 d2h_ctrl — Control Transfer packet sideband signals for Device to Host
    [16] srdy — Validity of d2h
    [15:4] time_tag — Event time tag recorded in each cycle.
    [3:2] vlane — Valid number of "lanes" where each lane is one bye
    [1] eop — End of Packet
    [0] sop — Start of Packet
  0x18 d2h_skip rw — This register allows the software to skip certain number of cycles in the d2h data and control registers.
    [7:0] cycles — Write once into this register with the number of cycles that the d2h_data and d2h_ctrl need to be skipped. A zero value will skip to the eop of the packet.
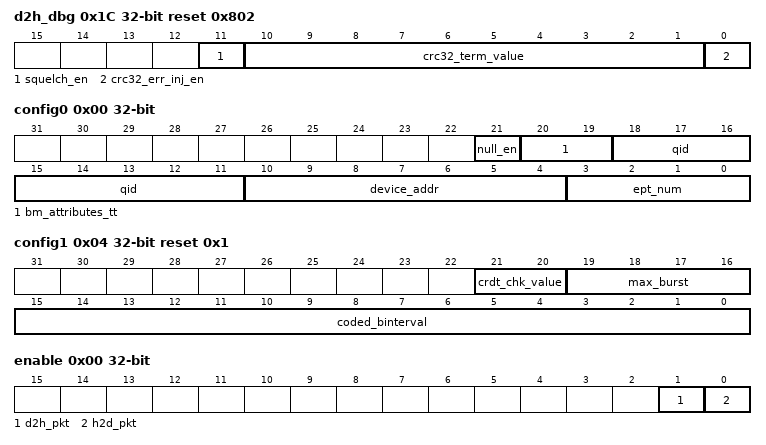
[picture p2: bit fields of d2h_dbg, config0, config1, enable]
  0x1C d2h_dbg rw reset 0x802
    [11] squelch_en — Set to 1 to zero out the data sent to the SW when injecting CRC32 error in the Control Transfer. Note that the data is squelched from the third cycle (from bytes 9) onwards, including the CRC32. Also note that the data is NOT squelched to the Host and only CRC32 is errored.
    [10:1] crc32_term_value — Every time a Control data packet is seen, a counter is incremented. When this terminus value is reached, the counter resets back to 0. Note value of 0 is NOT valid.
    [0] crc32_err_inj_en — Set to 1 to enable the CRC32 error injection logic and counter in the Control Transfers. When enabled, the counter is enabled and the logic will inject CRC32 errors when the crc32_term_value is reached in the counter.
  0x20 cmpltd rw — When Software completes processing a Control Transfer, it writes into this register to signal the completion of the processing for the Transfer
    [6:0] device_addr — Device Address that the Software completed processing its Control Transfer
0x2B0 endpoint_tbl group
  0x00 config0 rw — This register is used to configure the EndPoint Table (EPT) in the logic for IN Endpoints. It is the lowest 32 bit word. See config1 for the upper 32 bit word. Software shall write into this register to initiate and configure the EPT, when it has already written into the upper "word" (config1) NOTE**: A write into any field shall result in an update of the EPT. Therefore, the register should be updated once for a set of data and individual fields should not be written into unless other fields are kept as before. NOTE**: When writing into this "word", the data in the second "word" (config1) MUST be valid.
    [21] null_en — Set to 1 to null out the EndPoint. Currently, this only applies to the ISO EndPoints (bm_attributes_tt=1). When this bit is set, it blocks the ACK to reach the Device and terminates the ACK on the LEX by sending Null Data Packets to the Host. When this bit is set, the qid MUST be 0.
    [20:19] bm_attributes_tt — This field is configured based on the Transfer Type bits of bmAttritues of Table 9-24 in Section 9.6.6. Set to 0 to remove the EndPoint Set to 1 for ISO IN endpoints Set to 2 for Bulk IN endpoints set to 3 for Interrupts IN endpoints
    [18:11] qid — The Queue ID (QID) is the buffer number that the duality of is assigned to. The total number of QIDs available is reported in qid_total_num. Also, the up to date assignment of QIDs are reported in qid_assigned. Note that QID=0 is always assigned to "non-ISO" traffic needed in the logic and cannot be assigned by the software for any ISO traffic. However, when null_en is set, the qid MUST be 0 for the ISO EndPoints.
    [10:4] device_addr — This is the USB Device Address in the EPT
    [3:0] ept_num — This is the USB Endpoint Number in the EPT
  0x04 config1 rw reset 0x1 — This register is used to configure the EndPoint Table (EPT) in the logic for IN Endpoints. It is the highest 32 bit word. See config0 for the lower 32 bit word. NOTE**: The data in this "word" MUST be written before attempting to write into the lower "word" (config0).
    [21:20] crdt_chk_value — An indication of a "guard" before ITP boundary. It is a value of Total "Credit" (each one being a full DP) left before end of ITP. Typically, this should be zero. Any larger value could limit the bandwidth used.
    [19:16] max_burst — This field should be set such that it is not more than the Value of bMaxBurst of Section 9.6.7 and at the same time it does not impact the system performance with a large value. Typical values of 2 or 3 (if the device bMaxBurst is more than these values) could be a god compromise in most setups. If bMaxBurst is smaller than typical values above, this field should be the exact number equal to bMaxBurst.
    [15:0] coded_binterval — Hot coding to show the number of BInterval of Section 9.6.6. As example, BInterval=1 --->coded_binterval=2^0; BInterval=7 ---> coded_binterval=2^6; BInterval=16 ---> coded_binterval=2^15
  0x08 total_qid reset 0x1
    [7:0] total_qid — Total number of QID that has been implemented in the logic.
  0x0C qid_assigned0 reset 0x1
    [31:0] qid_assigned0 — One-hot encoded register that shows which QID is currently assigned. A one (1) in each bit position indicates that QID is already assigned.
0x2C0 stats0 group — All the Statistic Registers and their configuration
  0x00 rd2clr_config rw — Configures if the stats register read by s/w clears the read register. A 1 in any bit configures the h/w to clear the corresponding stats register after a s/w read of that stats register.
    [0] missing_itp
  0x04 missing_itp — Count the number ITP packets that did not receive at the REX
    [15:0] missing_itp
0x2C8 irq0 group — Define the IRQ group
  0x00 enable rw — The enable for the actual interrupt signals. Writing a 1 enables the interrupt.
    [1] d2h_pkt — Fires on availability of a packet in the Data to Host path in Control Transfer
    [0] h2d_pkt — Fires on availability of a packet in the Host to Data path in Control Transfer
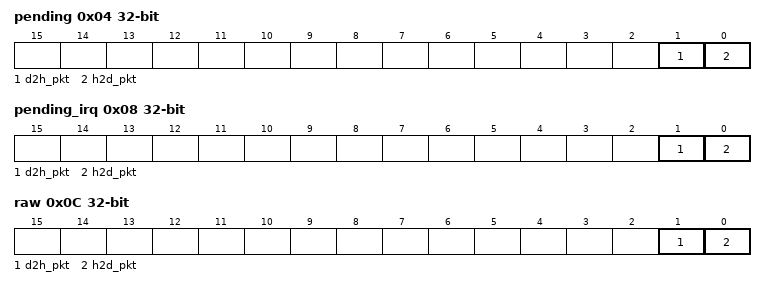
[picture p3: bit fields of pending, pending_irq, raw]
  0x04 pending rw — The actual interrupt(s) that has triggered. Write a 1 to clear.
    [1] d2h_pkt write-1-clears — Fires on availability of a packet in the Data to Host path in Control Transfer
    [0] h2d_pkt write-1-clears — Fires on availability of a packet in the Host to Data path in Control Transfer
  0x08 pending_irq — Registered version of pending & enable
    fields as irq0.enable
  0x0C raw — The status registered values for the interrupt signals, if applicable.
    [1] d2h_pkt — Not used
    [0] h2d_pkt — Not used
0x2D8 irq1 group — Define the IRQ group
  0x00 enable rw — The enable for the actual interrupt signals. Writing a 1 enables the interrupt.
    [31:16] ping_not_respond — Each bit fires on an ISO device not responding to PING REQUESTs for a defined number of times. The bit position refers to the EndPoint Queue.
    [15:0] iso_not_respond — Each bit fires on an ISO device not responding for a defined number of times. The bit position refers to the EndPoint Queue.
  0x04 pending rw — The actual interrupt(s) that has triggered. Write a 1 to clear.
    [31:16] ping_not_respond write-1-clears — Each bit fires on an ISO device not responding to PING REQUESTs for a defined number of times. The bit position refers to the EndPoint Queue.
    [15:0] iso_not_respond write-1-clears — Each bit fires on an ISO device not responding for a defined number of times. The bit position refers to the EndPoint Queue.
  0x08 pending_irq — Registered version of pending & enable
    fields as irq1.enable
  0x0C raw — The status registered values for the interrupt signals, if applicable.
    [31:16] ping_not_respond — Not used
    [15:0] iso_not_respond — Not used
